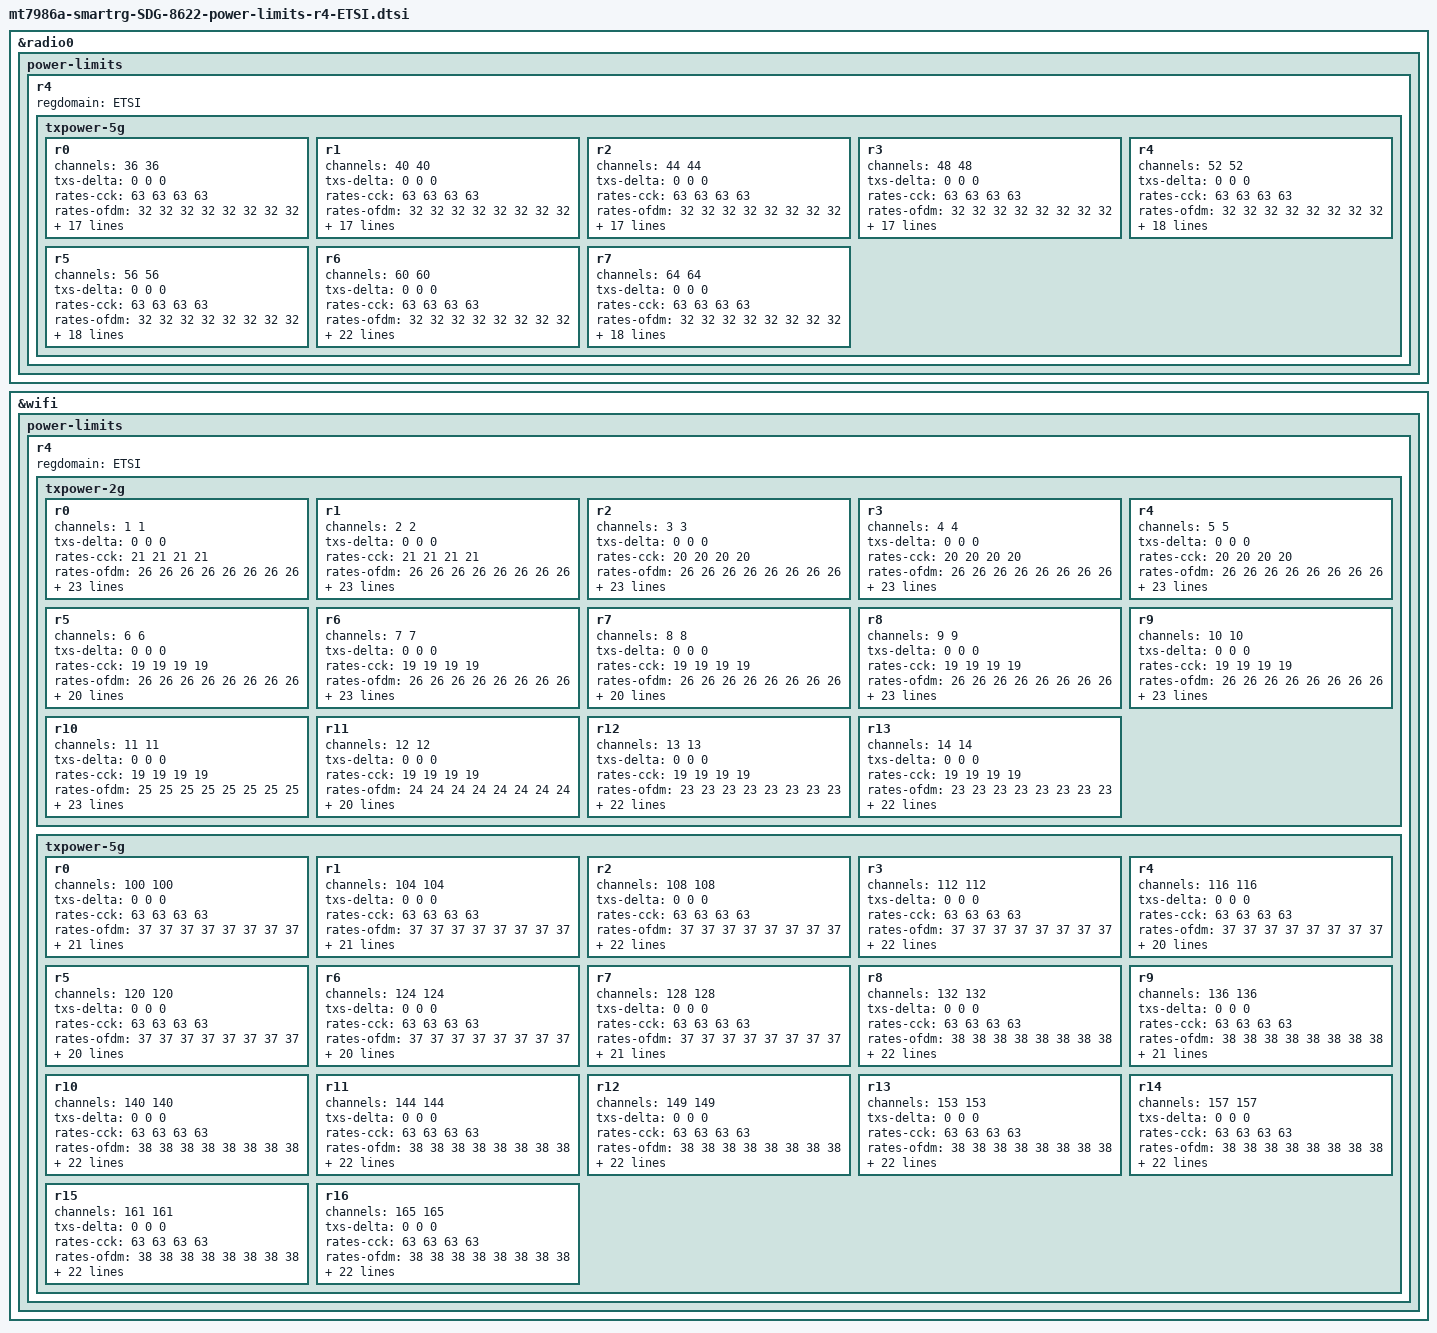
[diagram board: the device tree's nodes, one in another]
// SPDX-License-Identifier: (GPL-2.0 OR MIT)
/*
 * Copyright (C) 2022 SmartRG Inc.
 * Author: Chad Monroe <chad.monroe@smartrg.com>
 */

&radio0 {
	power-limits {
		r4 {
			regdomain = "ETSI";

			txpower-5g {
				r0 {
					channels = <36 36>;
					txs-delta = <0 0 0>;
					rates-cck = <63 63 63 63>;
					rates-ofdm = <32 32 32 32 32 32 32 32>;
					rates-mcs =
					<1 35 35 35 35 35 35 35 35 35 35>,
					<2 33 33 33 33 33 33 33 33 33 33>,
					<1 27 27 27 27 27 27 27 27 27 27>;
					rates-ru =
					<3 27 27 27 27 27 27 27 27 27 27 27 27>,
					<1 35 35 35 35 35 35 35 35 35 35 35 35>,
					<2 33 33 33 33 33 33 33 33 33 33 33 33>,
					<1 27 27 27 27 27 27 27 27 27 27 27 27>;
					paths-ofdm = <39 39 39 39>;
					paths-ofdm-bf = <0 40 40 40>;
					paths-ru =
					<3 27 27 27 27 27 27 27 27 27 27>,
					<1 35 35 35 35 35 35 35 35 35 35>,
					<2 33 33 33 33 33 33 33 33 33 33>,
					<1 27 27 27 27 27 27 27 27 27 27>;
					paths-ru-bf =
					<3 27 27 27 27 27 27 27 27 27 27>,
					<2 0 28 28 28 28 28 28 28 28 28>,
					<2 0 27 27 27 27 27 27 27 27 27>;
				};
				r1 {
					channels = <40 40>;
					txs-delta = <0 0 0>;
					rates-cck = <63 63 63 63>;
					rates-ofdm = <32 32 32 32 32 32 32 32>;
					rates-mcs =
					<1 35 35 35 35 35 35 35 35 35 35>,
					<2 33 33 33 33 33 33 33 33 33 33>,
					<1 27 27 27 27 27 27 27 27 27 27>;
					rates-ru =
					<3 27 27 27 27 27 27 27 27 27 27 27 27>,
					<1 35 35 35 35 35 35 35 35 35 35 35 35>,
					<2 33 33 33 33 33 33 33 33 33 33 33 33>,
					<1 27 27 27 27 27 27 27 27 27 27 27 27>;
					paths-ofdm = <40 40 40 40>;
					paths-ofdm-bf = <0 40 40 40>;
					paths-ru =
					<3 27 27 27 27 27 27 27 27 27 27>,
					<1 35 35 35 35 35 35 35 35 35 35>,
					<2 33 33 33 33 33 33 33 33 33 33>,
					<1 27 27 27 27 27 27 27 27 27 27>;
					paths-ru-bf =
					<3 27 27 27 27 27 27 27 27 27 27>,
					<2 0 28 28 28 28 28 28 28 28 28>,
					<2 0 27 27 27 27 27 27 27 27 27>;
				};
				r2 {
					channels = <44 44>;
					txs-delta = <0 0 0>;
					rates-cck = <63 63 63 63>;
					rates-ofdm = <32 32 32 32 32 32 32 32>;
					rates-mcs =
					<1 35 35 35 35 35 35 35 35 35 35>,
					<2 33 33 33 33 33 33 33 33 33 33>,
					<1 27 27 27 27 27 27 27 27 27 27>;
					rates-ru =
					<3 27 27 27 27 27 27 27 27 27 27 27 27>,
					<1 35 35 35 35 35 35 35 35 35 35 35 35>,
					<2 33 33 33 33 33 33 33 33 33 33 33 33>,
					<1 27 27 27 27 27 27 27 27 27 27 27 27>;
					paths-ofdm = <40 40 40 40>;
					paths-ofdm-bf = <0 40 40 40>;
					paths-ru =
					<3 27 27 27 27 27 27 27 27 27 27>,
					<1 35 35 35 35 35 35 35 35 35 35>,
					<2 33 33 33 33 33 33 33 33 33 33>,
					<1 27 27 27 27 27 27 27 27 27 27>;
					paths-ru-bf =
					<3 27 27 27 27 27 27 27 27 27 27>,
					<2 0 28 28 28 28 28 28 28 28 28>,
					<2 0 27 27 27 27 27 27 27 27 27>;
				};
				r3 {
					channels = <48 48>;
					txs-delta = <0 0 0>;
					rates-cck = <63 63 63 63>;
					rates-ofdm = <32 32 32 32 32 32 32 32>;
					rates-mcs =
					<1 35 35 35 35 35 35 35 35 35 35>,
					<2 33 33 33 33 33 33 33 33 33 33>,
					<1 27 27 27 27 27 27 27 27 27 27>;
					rates-ru =
					<3 27 27 27 27 27 27 27 27 27 27 27 27>,
					<1 35 35 35 35 35 35 35 35 35 35 35 35>,
					<2 33 33 33 33 33 33 33 33 33 33 33 33>,
					<1 27 27 27 27 27 27 27 27 27 27 27 27>;
					paths-ofdm = <39 39 39 39>;
					paths-ofdm-bf = <0 39 39 39>;
					paths-ru =
					<3 27 27 27 27 27 27 27 27 27 27>,
					<1 35 35 35 35 35 35 35 35 35 35>,
					<2 33 33 33 33 33 33 33 33 33 33>,
					<1 27 27 27 27 27 27 27 27 27 27>;
					paths-ru-bf =
					<3 27 27 27 27 27 27 27 27 27 27>,
					<2 0 28 28 28 28 28 28 28 28 28>,
					<2 0 27 27 27 27 27 27 27 27 27>;
				};
				r4 {
					channels = <52 52>;
					txs-delta = <0 0 0>;
					rates-cck = <63 63 63 63>;
					rates-ofdm = <32 32 32 32 32 32 32 32>;
					rates-mcs =
					<1 35 35 35 35 35 35 35 35 35 35>,
					<2 33 33 33 33 33 33 33 33 33 33>,
					<1 27 27 27 27 27 27 27 27 27 27>;
					rates-ru =
					<3 27 27 27 27 27 27 27 27 27 27 27 27>,
					<1 35 35 35 35 35 35 35 35 35 35 35 35>,
					<2 33 33 33 33 33 33 33 33 33 33 33 33>,
					<1 27 27 27 27 27 27 27 27 27 27 27 27>;
					paths-ofdm = <27 27 27 27>;
					paths-ofdm-bf = <0 27 27 27>;
					paths-ru =
					<3 27 27 27 27 27 27 27 27 27 27>,
					<1 35 35 35 35 35 35 35 35 35 35>,
					<2 33 33 33 33 33 33 33 33 33 33>,
					<1 27 27 27 27 27 27 27 27 27 27>;
					paths-ru-bf =
					<3 27 27 27 27 27 27 27 27 27 27>,
					<2 0 28 28 28 28 28 28 28 28 28>,
					<1 0 29 29 29 29 29 29 29 29 29>,
					<1 0 27 27 27 27 27 27 27 27 27>;
				};
				r5 {
					channels = <56 56>;
					txs-delta = <0 0 0>;
					rates-cck = <63 63 63 63>;
					rates-ofdm = <32 32 32 32 32 32 32 32>;
					rates-mcs =
					<1 35 35 35 35 35 35 35 35 35 35>,
					<2 33 33 33 33 33 33 33 33 33 33>,
					<1 27 27 27 27 27 27 27 27 27 27>;
					rates-ru =
					<3 27 27 27 27 27 27 27 27 27 27 27 27>,
					<1 35 35 35 35 35 35 35 35 35 35 35 35>,
					<2 33 33 33 33 33 33 33 33 33 33 33 33>,
					<1 27 27 27 27 27 27 27 27 27 27 27 27>;
					paths-ofdm = <27 27 27 27>;
					paths-ofdm-bf = <0 27 27 27>;
					paths-ru =
					<3 27 27 27 27 27 27 27 27 27 27>,
					<1 35 35 35 35 35 35 35 35 35 35>,
					<2 33 33 33 33 33 33 33 33 33 33>,
					<1 27 27 27 27 27 27 27 27 27 27>;
					paths-ru-bf =
					<3 27 27 27 27 27 27 27 27 27 27>,
					<2 0 28 28 28 28 28 28 28 28 28>,
					<1 0 29 29 29 29 29 29 29 29 29>,
					<1 0 27 27 27 27 27 27 27 27 27>;
				};
				r6 {
					channels = <60 60>;
					txs-delta = <0 0 0>;
					rates-cck = <63 63 63 63>;
					rates-ofdm = <32 32 32 32 32 32 32 32>;
					rates-mcs =
					<1 35 35 35 35 35 35 35 35 35 35>,
					<1 36 36 36 36 36 36 36 36 36 36>,
					<1 33 33 33 33 33 33 33 33 33 33>,
					<1 27 27 27 27 27 27 27 27 27 27>;
					rates-ru =
					<3 27 27 27 27 27 27 27 27 27 27 27 27>,
					<1 35 35 35 35 35 35 35 35 35 35 35 35>,
					<1 36 36 36 36 36 36 36 36 36 36 36 36>,
					<1 33 33 33 33 33 33 33 33 33 33 33 33>,
					<1 27 27 27 27 27 27 27 27 27 27 27 27>;
					paths-ofdm = <27 27 27 27>;
					paths-ofdm-bf = <0 27 27 27>;
					paths-ru =
					<3 27 27 27 27 27 27 27 27 27 27>,
					<1 35 35 35 35 35 35 35 35 35 35>,
					<1 36 36 36 36 36 36 36 36 36 36>,
					<1 33 33 33 33 33 33 33 33 33 33>,
					<1 27 27 27 27 27 27 27 27 27 27>;
					paths-ru-bf =
					<3 27 27 27 27 27 27 27 27 27 27>,
					<1 0 28 28 28 28 28 28 28 28 28>,
					<1 0 30 30 30 30 30 30 30 30 30>,
					<1 0 29 29 29 29 29 29 29 29 29>,
					<1 0 27 27 27 27 27 27 27 27 27>;
				};
				r7 {
					channels = <64 64>;
					txs-delta = <0 0 0>;
					rates-cck = <63 63 63 63>;
					rates-ofdm = <32 32 32 32 32 32 32 32>;
					rates-mcs =
					<2 36 36 36 36 36 36 36 36 36 36>,
					<1 33 33 33 33 33 33 33 33 33 33>,
					<1 27 27 27 27 27 27 27 27 27 27>;
					rates-ru =
					<3 27 27 27 27 27 27 27 27 27 27 27 27>,
					<2 36 36 36 36 36 36 36 36 36 36 36 36>,
					<1 33 33 33 33 33 33 33 33 33 33 33 33>,
					<1 27 27 27 27 27 27 27 27 27 27 27 27>;
					paths-ofdm = <27 27 27 27>;
					paths-ofdm-bf = <0 27 27 27>;
					paths-ru =
					<3 27 27 27 27 27 27 27 27 27 27>,
					<2 36 36 36 36 36 36 36 36 36 36>,
					<1 33 33 33 33 33 33 33 33 33 33>,
					<1 27 27 27 27 27 27 27 27 27 27>;
					paths-ru-bf =
					<3 27 27 27 27 27 27 27 27 27 27>,
					<2 0 30 30 30 30 30 30 30 30 30>,
					<1 0 29 29 29 29 29 29 29 29 29>,
					<1 0 27 27 27 27 27 27 27 27 27>;
				};
			};
		};
	};
};

&wifi {
	power-limits {
		r4 {
			regdomain = "ETSI";

			txpower-2g {
				r0 {
					channels = <1 1>;
					txs-delta = <0 0 0>;
					rates-cck = <21 21 21 21>;
					rates-ofdm = <26 26 26 26 26 26 26 26>;
					rates-mcs =
					<1 27 27 27 27 27 27 27 27 27 27>,
					<1 26 26 26 26 26 26 26 26 26 26>,
					<1 30 31 32 30 20 33 25 23 39 34>,
					<1 24 26 36 28 31 33 23 33 21 25>;
					rates-ru =
					<3 31 31 31 31 31 31 31 31 31 31 31 31>,
					<1 27 27 27 27 27 27 27 27 27 27 27 27>,
					<1 26 26 26 26 26 26 26 26 26 26 26 26>,
					<1 23 34 23 35 38 24 26 38 28 29 24 34>,
					<1 33 37 27 27 33 35 22 24 37 28 27 26>;
					paths-cck = <37 37 37 37>;
					paths-ofdm = <34 34 34 34>;
					paths-ofdm-bf = <0 33 33 33>;
					paths-ru =
					<3 28 28 28 28 28 28 28 28 28 28>,
					<1 27 27 27 27 27 27 27 27 27 27>,
					<1 26 26 26 26 26 26 26 26 26 26>,
					<1 27 38 20 26 28 20 29 21 36 30>,
					<1 35 39 24 31 25 30 25 29 27 39>;
					paths-ru-bf =
					<3 28 28 28 28 28 28 28 28 28 28>,
					<1 0 21 21 21 21 21 21 21 21 21>,
					<1 0 20 20 20 20 20 20 20 20 20>,
					<1 0 30 23 39 28 21 25 29 28 21>,
					<1 0 34 20 38 32 35 33 37 26 36>;
				};
				r1 {
					channels = <2 2>;
					txs-delta = <0 0 0>;
					rates-cck = <21 21 21 21>;
					rates-ofdm = <26 26 26 26 26 26 26 26>;
					rates-mcs =
					<1 27 27 27 27 27 27 27 27 27 27>,
					<1 26 26 26 26 26 26 26 26 26 26>,
					<1 29 26 37 20 35 27 31 23 27 23>,
					<1 28 33 25 28 27 23 24 33 24 21>;
					rates-ru =
					<3 31 31 31 31 31 31 31 31 31 31 31 31>,
					<1 27 27 27 27 27 27 27 27 27 27 27 27>,
					<1 26 26 26 26 26 26 26 26 26 26 26 26>,
					<1 28 22 29 39 21 39 29 24 23 32 25 21>,
					<1 23 32 30 39 29 27 36 26 22 33 34 29>;
					paths-cck = <38 38 38 38>;
					paths-ofdm = <35 35 35 35>;
					paths-ofdm-bf = <0 34 34 34>;
					paths-ru =
					<3 28 28 28 28 28 28 28 28 28 28>,
					<1 27 27 27 27 27 27 27 27 27 27>,
					<1 26 26 26 26 26 26 26 26 26 26>,
					<1 35 34 39 30 24 33 23 23 36 34>,
					<1 37 33 31 20 33 38 29 33 39 37>;
					paths-ru-bf =
					<3 28 28 28 28 28 28 28 28 28 28>,
					<1 0 21 21 21 21 21 21 21 21 21>,
					<1 0 20 20 20 20 20 20 20 20 20>,
					<1 0 29 21 24 33 24 30 22 22 31>,
					<1 0 38 34 33 23 25 39 30 31 32>;
				};
				r2 {
					channels = <3 3>;
					txs-delta = <0 0 0>;
					rates-cck = <20 20 20 20>;
					rates-ofdm = <26 26 26 26 26 26 26 26>;
					rates-mcs =
					<1 27 27 27 27 27 27 27 27 27 27>,
					<1 26 26 26 26 26 26 26 26 26 26>,
					<1 38 24 33 22 26 36 31 23 39 33>,
					<1 33 34 34 35 22 28 21 35 35 33>;
					rates-ru =
					<3 31 31 31 31 31 31 31 31 31 31 31 31>,
					<1 27 27 27 27 27 27 27 27 27 27 27 27>,
					<1 26 26 26 26 26 26 26 26 26 26 26 26>,
					<1 38 34 33 32 37 30 28 22 36 28 31 30>,
					<1 20 25 31 29 23 24 24 39 20 27 29 20>;
					paths-cck = <39 39 39 39>;
					paths-ofdm = <37 37 37 37>;
					paths-ofdm-bf = <0 35 35 35>;
					paths-ru =
					<3 28 28 28 28 28 28 28 28 28 28>,
					<1 27 27 27 27 27 27 27 27 27 27>,
					<1 26 26 26 26 26 26 26 26 26 26>,
					<1 30 38 34 37 35 31 39 20 26 23>,
					<1 33 25 35 25 32 27 35 22 29 35>;
					paths-ru-bf =
					<3 28 28 28 28 28 28 28 28 28 28>,
					<1 0 22 22 22 22 22 22 22 22 22>,
					<1 0 20 20 20 20 20 20 20 20 20>,
					<1 0 33 35 25 33 35 25 29 21 37>,
					<1 0 37 35 26 25 26 30 27 35 34>;
				};
				r3 {
					channels = <4 4>;
					txs-delta = <0 0 0>;
					rates-cck = <20 20 20 20>;
					rates-ofdm = <26 26 26 26 26 26 26 26>;
					rates-mcs =
					<1 27 27 27 27 27 27 27 27 27 27>,
					<1 26 26 26 26 26 26 26 26 26 26>,
					<1 38 23 25 21 27 38 20 23 39 36>,
					<1 23 24 20 26 37 31 29 30 22 36>;
					rates-ru =
					<3 31 31 31 31 31 31 31 31 31 31 31 31>,
					<1 27 27 27 27 27 27 27 27 27 27 27 27>,
					<1 26 26 26 26 26 26 26 26 26 26 26 26>,
					<1 37 34 38 35 35 39 38 26 39 37 24 34>,
					<1 29 31 24 39 24 22 20 28 34 31 30 21>;
					paths-cck = <41 41 41 41>;
					paths-ofdm = <39 39 39 39>;
					paths-ofdm-bf = <0 37 37 37>;
					paths-ru =
					<3 28 28 28 28 28 28 28 28 28 28>,
					<1 27 27 27 27 27 27 27 27 27 27>,
					<1 26 26 26 26 26 26 26 26 26 26>,
					<1 30 36 23 20 21 20 28 28 26 24>,
					<1 29 26 22 28 21 24 26 21 38 22>;
					paths-ru-bf =
					<3 28 28 28 28 28 28 28 28 28 28>,
					<1 0 22 22 22 22 22 22 22 22 22>,
					<1 0 20 20 20 20 20 20 20 20 20>,
					<1 0 28 37 30 26 20 38 35 21 27>,
					<1 0 39 39 32 25 26 33 32 33 25>;
				};
				r4 {
					channels = <5 5>;
					txs-delta = <0 0 0>;
					rates-cck = <20 20 20 20>;
					rates-ofdm = <26 26 26 26 26 26 26 26>;
					rates-mcs =
					<1 27 27 27 27 27 27 27 27 27 27>,
					<1 26 26 26 26 26 26 26 26 26 26>,
					<1 21 37 28 38 39 35 30 29 36 24>,
					<1 30 22 37 34 37 32 34 27 27 31>;
					rates-ru =
					<3 31 31 31 31 31 31 31 31 31 31 31 31>,
					<1 27 27 27 27 27 27 27 27 27 27 27 27>,
					<1 26 26 26 26 26 26 26 26 26 26 26 26>,
					<1 38 33 36 39 24 24 24 36 29 37 21 29>,
					<1 20 36 39 30 25 33 39 25 36 22 22 26>;
					paths-cck = <43 43 43 43>;
					paths-ofdm = <41 41 41 41>;
					paths-ofdm-bf = <0 38 38 38>;
					paths-ru =
					<3 28 28 28 28 28 28 28 28 28 28>,
					<1 27 27 27 27 27 27 27 27 27 27>,
					<1 26 26 26 26 26 26 26 26 26 26>,
					<1 25 31 23 25 27 25 26 28 25 34>,
					<1 29 38 27 22 37 25 33 35 34 31>;
					paths-ru-bf =
					<3 28 28 28 28 28 28 28 28 28 28>,
					<1 0 22 22 22 22 22 22 22 22 22>,
					<1 0 20 20 20 20 20 20 20 20 20>,
					<1 0 37 29 36 27 25 25 28 30 31>,
					<1 0 23 26 34 34 37 37 23 23 38>;
				};
				r5 {
					channels = <6 6>;
					txs-delta = <0 0 0>;
					rates-cck = <19 19 19 19>;
					rates-ofdm = <26 26 26 26 26 26 26 26>;
					rates-mcs =
					<2 27 27 27 27 27 27 27 27 27 27>,
					<1 33 39 30 36 33 37 38 39 38 35>,
					<1 29 23 22 36 23 21 28 35 36 33>;
					rates-ru =
					<3 31 31 31 31 31 31 31 31 31 31 31 31>,
					<2 27 27 27 27 27 27 27 27 27 27 27 27>,
					<1 23 23 31 30 21 30 27 33 27 23 31 23>,
					<1 39 36 25 24 38 36 24 30 29 39 21 22>;
					paths-cck = <44 44 44 44>;
					paths-ofdm = <42 42 42 42>;
					paths-ofdm-bf = <0 39 39 39>;
					paths-ru =
					<3 28 28 28 28 28 28 28 28 28 28>,
					<2 27 27 27 27 27 27 27 27 27 27>,
					<1 39 28 27 38 36 28 38 23 25 30>,
					<1 30 37 27 24 34 33 39 29 29 24>;
					paths-ru-bf =
					<3 28 28 28 28 28 28 28 28 28 28>,
					<1 0 22 22 22 22 22 22 22 22 22>,
					<1 0 20 20 20 20 20 20 20 20 20>,
					<1 0 33 24 27 27 36 22 26 27 38>,
					<1 0 20 30 32 26 39 36 28 38 34>;
				};
				r6 {
					channels = <7 7>;
					txs-delta = <0 0 0>;
					rates-cck = <19 19 19 19>;
					rates-ofdm = <26 26 26 26 26 26 26 26>;
					rates-mcs =
					<1 27 27 27 27 27 27 27 27 27 27>,
					<1 28 28 28 28 28 28 28 28 28 28>,
					<1 22 29 34 29 20 28 37 32 28 38>,
					<1 31 23 31 36 25 21 23 23 23 36>;
					rates-ru =
					<3 31 31 31 31 31 31 31 31 31 31 31 31>,
					<1 27 27 27 27 27 27 27 27 27 27 27 27>,
					<1 28 28 28 28 28 28 28 28 28 28 28 28>,
					<1 34 24 28 32 24 39 21 39 25 39 34 21>,
					<1 33 24 24 24 28 31 39 36 31 23 20 25>;
					paths-cck = <43 43 43 43>;
					paths-ofdm = <41 41 41 41>;
					paths-ofdm-bf = <0 37 37 37>;
					paths-ru =
					<3 28 28 28 28 28 28 28 28 28 28>,
					<1 27 27 27 27 27 27 27 27 27 27>,
					<1 28 28 28 28 28 28 28 28 28 28>,
					<1 24 26 29 29 32 34 26 29 21 37>,
					<1 27 33 25 22 35 20 37 32 30 37>;
					paths-ru-bf =
					<3 28 28 28 28 28 28 28 28 28 28>,
					<1 0 22 22 22 22 22 22 22 22 22>,
					<1 0 20 20 20 20 20 20 20 20 20>,
					<1 0 26 24 27 31 28 22 31 23 32>,
					<1 0 21 33 37 38 34 25 36 39 27>;
				};
				r7 {
					channels = <8 8>;
					txs-delta = <0 0 0>;
					rates-cck = <19 19 19 19>;
					rates-ofdm = <26 26 26 26 26 26 26 26>;
					rates-mcs =
					<2 27 27 27 27 27 27 27 27 27 27>,
					<1 27 20 34 28 20 20 30 36 31 35>,
					<1 37 20 34 38 35 28 20 32 21 25>;
					rates-ru =
					<3 31 31 31 31 31 31 31 31 31 31 31 31>,
					<2 27 27 27 27 27 27 27 27 27 27 27 27>,
					<1 21 28 28 37 39 27 21 36 29 24 28 32>,
					<1 26 27 22 28 32 20 30 26 29 28 31 38>;
					paths-cck = <41 41 41 41>;
					paths-ofdm = <39 39 39 39>;
					paths-ofdm-bf = <0 35 35 35>;
					paths-ru =
					<3 28 28 28 28 28 28 28 28 28 28>,
					<2 27 27 27 27 27 27 27 27 27 27>,
					<1 32 29 31 34 25 30 25 26 36 31>,
					<1 21 33 36 36 36 32 27 31 38 26>;
					paths-ru-bf =
					<3 28 28 28 28 28 28 28 28 28 28>,
					<1 0 22 22 22 22 22 22 22 22 22>,
					<1 0 20 20 20 20 20 20 20 20 20>,
					<1 0 24 29 21 27 21 25 39 35 21>,
					<1 0 36 38 38 32 30 32 39 28 34>;
				};
				r8 {
					channels = <9 9>;
					txs-delta = <0 0 0>;
					rates-cck = <19 19 19 19>;
					rates-ofdm = <26 26 26 26 26 26 26 26>;
					rates-mcs =
					<1 27 27 27 27 27 27 27 27 27 27>,
					<1 26 26 26 26 26 26 26 26 26 26>,
					<1 25 25 27 35 32 35 20 30 32 37>,
					<1 36 34 38 30 35 39 36 33 20 25>;
					rates-ru =
					<3 31 31 31 31 31 31 31 31 31 31 31 31>,
					<1 27 27 27 27 27 27 27 27 27 27 27 27>,
					<1 26 26 26 26 26 26 26 26 26 26 26 26>,
					<1 37 22 30 38 26 27 28 23 28 31 26 39>,
					<1 22 39 29 24 39 35 34 37 38 36 29 27>;
					paths-cck = <39 39 39 39>;
					paths-ofdm = <37 37 37 37>;
					paths-ofdm-bf = <0 33 33 33>;
					paths-ru =
					<3 28 28 28 28 28 28 28 28 28 28>,
					<1 27 27 27 27 27 27 27 27 27 27>,
					<1 26 26 26 26 26 26 26 26 26 26>,
					<1 24 27 27 22 25 33 24 32 23 21>,
					<1 33 22 27 35 34 30 21 25 20 35>;
					paths-ru-bf =
					<3 28 28 28 28 28 28 28 28 28 28>,
					<1 0 22 22 22 22 22 22 22 22 22>,
					<1 0 20 20 20 20 20 20 20 20 20>,
					<1 0 24 25 31 20 30 28 34 29 22>,
					<1 0 30 22 26 33 29 37 39 32 37>;
				};
				r9 {
					channels = <10 10>;
					txs-delta = <0 0 0>;
					rates-cck = <19 19 19 19>;
					rates-ofdm = <26 26 26 26 26 26 26 26>;
					rates-mcs =
					<1 27 27 27 27 27 27 27 27 27 27>,
					<1 26 26 26 26 26 26 26 26 26 26>,
					<1 31 39 34 29 38 29 38 35 24 20>,
					<1 36 34 25 32 32 28 39 25 35 24>;
					rates-ru =
					<3 31 31 31 31 31 31 31 31 31 31 31 31>,
					<1 27 27 27 27 27 27 27 27 27 27 27 27>,
					<1 26 26 26 26 26 26 26 26 26 26 26 26>,
					<1 36 31 30 32 20 24 39 25 36 29 22 28>,
					<1 32 28 37 35 24 25 20 38 35 33 29 27>;
					paths-cck = <38 38 38 38>;
					paths-ofdm = <35 35 35 35>;
					paths-ofdm-bf = <0 31 31 31>;
					paths-ru =
					<3 28 28 28 28 28 28 28 28 28 28>,
					<1 27 27 27 27 27 27 27 27 27 27>,
					<1 26 26 26 26 26 26 26 26 26 26>,
					<1 27 21 34 30 22 38 30 22 32 38>,
					<1 30 33 34 33 32 24 39 28 39 35>;
					paths-ru-bf =
					<3 28 28 28 28 28 28 28 28 28 28>,
					<1 0 22 22 22 22 22 22 22 22 22>,
					<1 0 20 20 20 20 20 20 20 20 20>,
					<1 0 35 30 38 21 38 23 21 35 28>,
					<1 0 36 35 21 30 38 23 32 33 31>;
				};
				r10 {
					channels = <11 11>;
					txs-delta = <0 0 0>;
					rates-cck = <19 19 19 19>;
					rates-ofdm = <25 25 25 25 25 25 25 25>;
					rates-mcs =
					<1 27 27 27 27 27 27 27 27 27 27>,
					<1 26 26 26 26 26 26 26 26 26 26>,
					<1 23 26 33 31 26 21 38 34 39 20>,
					<1 29 30 22 31 34 33 28 34 24 20>;
					rates-ru =
					<3 31 31 31 31 31 31 31 31 31 31 31 31>,
					<1 27 27 27 27 27 27 27 27 27 27 27 27>,
					<1 26 26 26 26 26 26 26 26 26 26 26 26>,
					<1 29 24 30 33 37 39 36 36 29 36 24 26>,
					<1 25 28 33 34 34 23 22 36 33 35 22 24>;
					paths-cck = <37 37 37 37>;
					paths-ofdm = <34 34 34 34>;
					paths-ofdm-bf = <0 29 29 29>;
					paths-ru =
					<3 28 28 28 28 28 28 28 28 28 28>,
					<1 27 27 27 27 27 27 27 27 27 27>,
					<1 26 26 26 26 26 26 26 26 26 26>,
					<1 26 38 39 25 37 26 32 38 36 24>,
					<1 23 36 27 26 29 36 28 31 36 37>;
					paths-ru-bf =
					<3 28 28 28 28 28 28 28 28 28 28>,
					<1 0 22 22 22 22 22 22 22 22 22>,
					<1 0 20 20 20 20 20 20 20 20 20>,
					<1 0 35 23 38 35 37 27 37 26 22>,
					<1 0 24 25 36 38 30 20 27 22 29>;
				};
				r11 {
					channels = <12 12>;
					txs-delta = <0 0 0>;
					rates-cck = <19 19 19 19>;
					rates-ofdm = <24 24 24 24 24 24 24 24>;
					rates-mcs =
					<2 26 26 26 26 26 26 26 26 26 26>,
					<1 20 36 37 24 24 29 34 27 31 24>,
					<1 29 22 21 38 24 25 31 23 20 21>;
					rates-ru =
					<3 31 31 31 31 31 31 31 31 31 31 31 31>,
					<2 26 26 26 26 26 26 26 26 26 26 26 26>,
					<1 31 26 23 24 36 34 24 30 24 25 31 24>,
					<1 35 23 20 39 28 25 24 30 34 33 32 32>;
					paths-cck = <37 37 37 37>;
					paths-ofdm = <34 34 34 34>;
					paths-ofdm-bf = <0 29 29 29>;
					paths-ru =
					<3 28 28 28 28 28 28 28 28 28 28>,
					<2 26 26 26 26 26 26 26 26 26 26>,
					<1 25 23 35 29 35 20 23 39 36 24>,
					<1 34 21 30 34 24 24 24 32 23 31>;
					paths-ru-bf =
					<3 28 28 28 28 28 28 28 28 28 28>,
					<1 0 21 21 21 21 21 21 21 21 21>,
					<1 0 20 20 20 20 20 20 20 20 20>,
					<1 0 25 25 20 21 25 29 37 29 22>,
					<1 0 29 37 25 37 35 31 30 39 39>;
				};
				r12 {
					channels = <13 13>;
					txs-delta = <0 0 0>;
					rates-cck = <19 19 19 19>;
					rates-ofdm = <23 23 23 23 23 23 23 23>;
					rates-mcs =
					<1 25 25 25 25 25 25 25 25 25 25>,
					<1 26 26 26 26 26 26 26 26 26 26>,
					<1 29 24 37 23 38 36 39 32 35 33>,
					<1 21 26 33 29 27 28 34 36 23 32>;
					rates-ru =
					<3 31 31 31 31 31 31 31 31 31 31 31 31>,
					<1 25 25 25 25 25 25 25 25 25 25 25 25>,
					<1 26 26 26 26 26 26 26 26 26 26 26 26>,
					<1 34 34 36 28 28 35 30 34 24 32 27 36>,
					<1 34 30 24 34 36 36 20 23 25 31 31 20>;
					paths-cck = <37 37 37 37>;
					paths-ofdm = <34 34 34 34>;
					paths-ofdm-bf = <0 29 29 29>;
					paths-ru =
					<3 28 28 28 28 28 28 28 28 28 28>,
					<1 25 25 25 25 25 25 25 25 25 25>,
					<1 26 26 26 26 26 26 26 26 26 26>,
					<1 28 23 27 25 39 20 23 27 36 30>,
					<1 25 23 34 26 37 26 32 37 36 31>;
					paths-ru-bf =
					<3 28 28 28 28 28 28 28 28 28 28>,
					<2 0 20 20 20 20 20 20 20 20 20>,
					<1 0 31 32 31 34 33 27 36 22 20>,
					<1 0 32 25 23 39 20 28 37 21 32>;
				};
				r13 {
					channels = <14 14>;
					txs-delta = <0 0 0>;
					rates-cck = <19 19 19 19>;
					rates-ofdm = <23 23 23 23 23 23 23 23>;
					rates-mcs =
					<1 25 25 25 25 25 25 25 25 25 25>,
					<1 26 26 26 26 26 26 26 26 26 26>,
					<1 38 29 37 27 28 24 32 37 33 22>,
					<1 31 37 23 28 23 35 21 22 20 34>;
					rates-ru =
					<3 31 31 31 31 31 31 31 31 31 31 31 31>,
					<1 25 25 25 25 25 25 25 25 25 25 25 25>,
					<1 26 26 26 26 26 26 26 26 26 26 26 26>,
					<1 30 28 21 29 34 23 32 31 24 26 36 30>,
					<1 22 28 32 29 24 20 23 21 33 33 22 24>;
					paths-cck = <37 37 37 37>;
					paths-ofdm = <34 34 34 34>;
					paths-ofdm-bf = <0 29 29 29>;
					paths-ru =
					<3 28 28 28 28 28 28 28 28 28 28>,
					<1 25 25 25 25 25 25 25 25 25 25>,
					<1 26 26 26 26 26 26 26 26 26 26>,
					<1 26 36 26 37 26 20 36 21 30 30>,
					<1 24 33 33 27 25 27 29 39 37 30>;
					paths-ru-bf =
					<3 28 28 28 28 28 28 28 28 28 28>,
					<2 0 20 20 20 20 20 20 20 20 20>,
					<1 0 36 24 22 27 32 29 36 36 37>,
					<1 0 33 29 29 36 32 29 36 25 39>;
				};
			};

			txpower-5g {
				r0 {
					channels = <100 100>;
					txs-delta = <0 0 0>;
					rates-cck = <63 63 63 63>;
					rates-ofdm = <37 37 37 37 37 37 37 37>;
					rates-mcs =
					<1 35 35 35 35 35 35 35 35 35 35>,
					<1 36 36 36 36 36 36 36 36 36 36>,
					<1 34 34 34 34 34 34 34 34 34 34>,
					<1 32 32 32 32 32 32 32 32 32 32>;
					rates-ru =
					<3 27 27 27 27 27 27 27 27 27 27 27 27>,
					<1 35 35 35 35 35 35 35 35 35 35 35 35>,
					<1 36 36 36 36 36 36 36 36 36 36 36 36>,
					<1 34 34 34 34 34 34 34 34 34 34 34 34>,
					<1 32 32 32 32 32 32 32 32 32 32 32 32>;
					paths-ofdm = <27 27 27 27>;
					paths-ofdm-bf = <0 27 27 27>;
					paths-ru =
					<3 27 27 27 27 27 27 27 27 27 27>,
					<1 35 35 35 35 35 35 35 35 35 35>,
					<1 36 36 36 36 36 36 36 36 36 36>,
					<1 34 34 34 34 34 34 34 34 34 34>,
					<1 32 32 32 32 32 32 32 32 32 32>;
					paths-ru-bf =
					<3 27 27 27 27 27 27 27 27 27 27>,
					<1 0 36 36 36 36 36 36 36 36 36>,
					<2 0 32 32 32 32 32 32 32 32 32>,
					<1 0 34 34 34 34 34 34 34 34 34>;
				};
				r1 {
					channels = <104 104>;
					txs-delta = <0 0 0>;
					rates-cck = <63 63 63 63>;
					rates-ofdm = <37 37 37 37 37 37 37 37>;
					rates-mcs =
					<1 35 35 35 35 35 35 35 35 35 35>,
					<1 36 36 36 36 36 36 36 36 36 36>,
					<1 34 34 34 34 34 34 34 34 34 34>,
					<1 32 32 32 32 32 32 32 32 32 32>;
					rates-ru =
					<3 27 27 27 27 27 27 27 27 27 27 27 27>,
					<1 35 35 35 35 35 35 35 35 35 35 35 35>,
					<1 36 36 36 36 36 36 36 36 36 36 36 36>,
					<1 34 34 34 34 34 34 34 34 34 34 34 34>,
					<1 32 32 32 32 32 32 32 32 32 32 32 32>;
					paths-ofdm = <28 28 28 28>;
					paths-ofdm-bf = <0 28 28 28>;
					paths-ru =
					<3 27 27 27 27 27 27 27 27 27 27>,
					<1 35 35 35 35 35 35 35 35 35 35>,
					<1 36 36 36 36 36 36 36 36 36 36>,
					<1 34 34 34 34 34 34 34 34 34 34>,
					<1 32 32 32 32 32 32 32 32 32 32>;
					paths-ru-bf =
					<3 27 27 27 27 27 27 27 27 27 27>,
					<1 0 36 36 36 36 36 36 36 36 36>,
					<2 0 32 32 32 32 32 32 32 32 32>,
					<1 0 34 34 34 34 34 34 34 34 34>;
				};
				r2 {
					channels = <108 108>;
					txs-delta = <0 0 0>;
					rates-cck = <63 63 63 63>;
					rates-ofdm = <37 37 37 37 37 37 37 37>;
					rates-mcs =
					<1 35 35 35 35 35 35 35 35 35 35>,
					<1 37 37 37 37 37 37 37 37 37 37>,
					<1 34 34 34 34 34 34 34 34 34 34>,
					<1 32 32 32 32 32 32 32 32 32 32>;
					rates-ru =
					<3 27 27 27 27 27 27 27 27 27 27 27 27>,
					<1 35 35 35 35 35 35 35 35 35 35 35 35>,
					<1 37 37 37 37 37 37 37 37 37 37 37 37>,
					<1 34 34 34 34 34 34 34 34 34 34 34 34>,
					<1 32 32 32 32 32 32 32 32 32 32 32 32>;
					paths-ofdm = <28 28 28 28>;
					paths-ofdm-bf = <0 28 28 28>;
					paths-ru =
					<3 27 27 27 27 27 27 27 27 27 27>,
					<1 35 35 35 35 35 35 35 35 35 35>,
					<1 37 37 37 37 37 37 37 37 37 37>,
					<1 34 34 34 34 34 34 34 34 34 34>,
					<1 32 32 32 32 32 32 32 32 32 32>;
					paths-ru-bf =
					<3 27 27 27 27 27 27 27 27 27 27>,
					<1 0 36 36 36 36 36 36 36 36 36>,
					<1 0 33 33 33 33 33 33 33 33 33>,
					<1 0 32 32 32 32 32 32 32 32 32>,
					<1 0 34 34 34 34 34 34 34 34 34>;
				};
				r3 {
					channels = <112 112>;
					txs-delta = <0 0 0>;
					rates-cck = <63 63 63 63>;
					rates-ofdm = <37 37 37 37 37 37 37 37>;
					rates-mcs =
					<1 35 35 35 35 35 35 35 35 35 35>,
					<1 37 37 37 37 37 37 37 37 37 37>,
					<1 34 34 34 34 34 34 34 34 34 34>,
					<1 32 32 32 32 32 32 32 32 32 32>;
					rates-ru =
					<3 27 27 27 27 27 27 27 27 27 27 27 27>,
					<1 35 35 35 35 35 35 35 35 35 35 35 35>,
					<1 37 37 37 37 37 37 37 37 37 37 37 37>,
					<1 34 34 34 34 34 34 34 34 34 34 34 34>,
					<1 32 32 32 32 32 32 32 32 32 32 32 32>;
					paths-ofdm = <28 28 28 28>;
					paths-ofdm-bf = <0 28 28 28>;
					paths-ru =
					<3 27 27 27 27 27 27 27 27 27 27>,
					<1 35 35 35 35 35 35 35 35 35 35>,
					<1 37 37 37 37 37 37 37 37 37 37>,
					<1 34 34 34 34 34 34 34 34 34 34>,
					<1 32 32 32 32 32 32 32 32 32 32>;
					paths-ru-bf =
					<3 27 27 27 27 27 27 27 27 27 27>,
					<1 0 36 36 36 36 36 36 36 36 36>,
					<1 0 33 33 33 33 33 33 33 33 33>,
					<1 0 32 32 32 32 32 32 32 32 32>,
					<1 0 34 34 34 34 34 34 34 34 34>;
				};
				r4 {
					channels = <116 116>;
					txs-delta = <0 0 0>;
					rates-cck = <63 63 63 63>;
					rates-ofdm = <37 37 37 37 37 37 37 37>;
					rates-mcs =
					<1 36 36 36 36 36 36 36 36 36 36>,
					<1 38 38 38 38 38 38 38 38 38 38>,
					<1 36 36 36 36 36 36 36 36 36 36>,
					<1 32 32 32 32 32 32 32 32 32 32>;
					rates-ru =
					<3 27 27 27 27 27 27 27 27 27 27 27 27>,
					<1 36 36 36 36 36 36 36 36 36 36 36 36>,
					<1 38 38 38 38 38 38 38 38 38 38 38 38>,
					<1 36 36 36 36 36 36 36 36 36 36 36 36>,
					<1 32 32 32 32 32 32 32 32 32 32 32 32>;
					paths-ofdm = <28 28 28 28>;
					paths-ofdm-bf = <0 28 28 28>;
					paths-ru =
					<3 27 27 27 27 27 27 27 27 27 27>,
					<1 36 36 36 36 36 36 36 36 36 36>,
					<1 38 38 38 38 38 38 38 38 38 38>,
					<1 36 36 36 36 36 36 36 36 36 36>,
					<1 32 32 32 32 32 32 32 32 32 32>;
					paths-ru-bf =
					<3 27 27 27 27 27 27 27 27 27 27>,
					<1 0 36 36 36 36 36 36 36 36 36>,
					<3 0 34 34 34 34 34 34 34 34 34>;
				};
				r5 {
					channels = <120 120>;
					txs-delta = <0 0 0>;
					rates-cck = <63 63 63 63>;
					rates-ofdm = <37 37 37 37 37 37 37 37>;
					rates-mcs =
					<1 36 36 36 36 36 36 36 36 36 36>,
					<1 38 38 38 38 38 38 38 38 38 38>,
					<1 36 36 36 36 36 36 36 36 36 36>,
					<1 32 32 32 32 32 32 32 32 32 32>;
					rates-ru =
					<3 27 27 27 27 27 27 27 27 27 27 27 27>,
					<1 36 36 36 36 36 36 36 36 36 36 36 36>,
					<1 38 38 38 38 38 38 38 38 38 38 38 38>,
					<1 36 36 36 36 36 36 36 36 36 36 36 36>,
					<1 32 32 32 32 32 32 32 32 32 32 32 32>;
					paths-ofdm = <28 21 20 39>;
					paths-ofdm-bf = <0 22 35 28>;
					paths-ru =
					<3 27 27 27 27 27 27 27 27 27 27>,
					<1 36 36 36 36 36 36 36 36 36 36>,
					<1 38 38 38 38 38 38 38 38 38 38>,
					<1 36 36 36 36 36 36 36 36 36 36>,
					<1 32 32 32 32 32 32 32 32 32 32>;
					paths-ru-bf =
					<3 27 27 27 27 27 27 27 27 27 27>,
					<1 0 36 36 36 36 36 36 36 36 36>,
					<3 0 34 34 34 34 34 34 34 34 34>;
				};
				r6 {
					channels = <124 124>;
					txs-delta = <0 0 0>;
					rates-cck = <63 63 63 63>;
					rates-ofdm = <37 37 37 37 37 37 37 37>;
					rates-mcs =
					<1 36 36 36 36 36 36 36 36 36 36>,
					<1 39 39 39 39 39 39 39 39 39 39>,
					<1 36 36 36 36 36 36 36 36 36 36>,
					<1 32 32 32 32 32 32 32 32 32 32>;
					rates-ru =
					<3 27 27 27 27 27 27 27 27 27 27 27 27>,
					<1 36 36 36 36 36 36 36 36 36 36 36 36>,
					<1 39 39 39 39 39 39 39 39 39 39 39 39>,
					<1 36 36 36 36 36 36 36 36 36 36 36 36>,
					<1 32 32 32 32 32 32 32 32 32 32 32 32>;
					paths-ofdm = <28 37 33 28>;
					paths-ofdm-bf = <0 22 26 33>;
					paths-ru =
					<3 27 27 27 27 27 27 27 27 27 27>,
					<1 36 36 36 36 36 36 36 36 36 36>,
					<1 39 39 39 39 39 39 39 39 39 39>,
					<1 36 36 36 36 36 36 36 36 36 36>,
					<1 32 32 32 32 32 32 32 32 32 32>;
					paths-ru-bf =
					<3 27 27 27 27 27 27 27 27 27 27>,
					<2 0 35 35 35 35 35 35 35 35 35>,
					<2 0 34 34 34 34 34 34 34 34 34>;
				};
				r7 {
					channels = <128 128>;
					txs-delta = <0 0 0>;
					rates-cck = <63 63 63 63>;
					rates-ofdm = <37 37 37 37 37 37 37 37>;
					rates-mcs =
					<1 36 36 36 36 36 36 36 36 36 36>,
					<1 39 39 39 39 39 39 39 39 39 39>,
					<1 36 36 36 36 36 36 36 36 36 36>,
					<1 32 32 32 32 32 32 32 32 32 32>;
					rates-ru =
					<3 27 27 27 27 27 27 27 27 27 27 27 27>,
					<1 36 36 36 36 36 36 36 36 36 36 36 36>,
					<1 39 39 39 39 39 39 39 39 39 39 39 39>,
					<1 36 36 36 36 36 36 36 36 36 36 36 36>,
					<1 32 32 32 32 32 32 32 32 32 32 32 32>;
					paths-ofdm = <28 24 29 37>;
					paths-ofdm-bf = <0 20 32 30>;
					paths-ru =
					<3 27 27 27 27 27 27 27 27 27 27>,
					<1 36 36 36 36 36 36 36 36 36 36>,
					<1 39 39 39 39 39 39 39 39 39 39>,
					<1 36 36 36 36 36 36 36 36 36 36>,
					<1 32 32 32 32 32 32 32 32 32 32>;
					paths-ru-bf =
					<3 27 27 27 27 27 27 27 27 27 27>,
					<1 0 34 34 34 34 34 34 34 34 34>,
					<1 0 35 35 35 35 35 35 35 35 35>,
					<2 0 34 34 34 34 34 34 34 34 34>;
				};
				r8 {
					channels = <132 132>;
					txs-delta = <0 0 0>;
					rates-cck = <63 63 63 63>;
					rates-ofdm = <38 38 38 38 38 38 38 38>;
					rates-mcs =
					<1 37 37 37 37 37 37 37 37 37 37>,
					<1 39 39 39 39 39 39 39 39 39 39>,
					<1 36 36 36 36 36 36 36 36 36 36>,
					<1 30 27 24 30 27 24 35 31 38 39>;
					rates-ru =
					<3 27 27 27 27 27 27 27 27 27 27 27 27>,
					<1 37 37 37 37 37 37 37 37 37 37 37 37>,
					<1 39 39 39 39 39 39 39 39 39 39 39 39>,
					<1 36 36 36 36 36 36 36 36 36 36 36 36>,
					<1 27 27 27 27 27 27 27 27 27 27 27 27>;
					paths-ofdm = <28 31 36 32>;
					paths-ofdm-bf = <0 20 29 21>;
					paths-ru =
					<3 27 27 27 27 27 27 27 27 27 27>,
					<1 37 37 37 37 37 37 37 37 37 37>,
					<1 39 39 39 39 39 39 39 39 39 39>,
					<1 36 36 36 36 36 36 36 36 36 36>,
					<1 30 30 30 30 30 30 30 30 30 30>;
					paths-ru-bf =
					<3 27 27 27 27 27 27 27 27 27 27>,
					<1 0 33 33 33 33 33 33 33 33 33>,
					<1 0 35 35 35 35 35 35 35 35 35>,
					<1 0 34 34 34 34 34 34 34 34 34>,
					<1 0 34 20 24 20 33 23 38 26 25>;
				};
				r9 {
					channels = <136 136>;
					txs-delta = <0 0 0>;
					rates-cck = <63 63 63 63>;
					rates-ofdm = <38 38 38 38 38 38 38 38>;
					rates-mcs =
					<1 37 37 37 37 37 37 37 37 37 37>,
					<1 39 39 39 39 39 39 39 39 39 39>,
					<1 36 36 36 36 36 36 36 36 36 36>,
					<1 36 37 38 34 22 33 32 23 24 37>;
					rates-ru =
					<3 27 27 27 27 27 27 27 27 27 27 27 27>,
					<1 37 37 37 37 37 37 37 37 37 37 37 37>,
					<1 39 39 39 39 39 39 39 39 39 39 39 39>,
					<1 36 36 36 36 36 36 36 36 36 36 36 36>,
					<1 27 27 27 27 27 27 27 27 27 27 27 27>;
					paths-ofdm = <28 20 26 27>;
					paths-ofdm-bf = <0 31 39 36>;
					paths-ru =
					<3 27 27 27 27 27 27 27 27 27 27>,
					<1 37 37 37 37 37 37 37 37 37 37>,
					<1 39 39 39 39 39 39 39 39 39 39>,
					<2 36 36 36 36 36 36 36 36 36 36>;
					paths-ru-bf =
					<3 27 27 27 27 27 27 27 27 27 27>,
					<1 0 32 32 32 32 32 32 32 32 32>,
					<1 0 35 35 35 35 35 35 35 35 35>,
					<1 0 34 34 34 34 34 34 34 34 34>,
					<1 0 22 30 27 30 31 34 36 34 27>;
				};
				r10 {
					channels = <140 140>;
					txs-delta = <0 0 0>;
					rates-cck = <63 63 63 63>;
					rates-ofdm = <38 38 38 38 38 38 38 38>;
					rates-mcs =
					<1 37 37 37 37 37 37 37 37 37 37>,
					<1 39 39 39 39 39 39 39 39 39 39>,
					<1 36 36 36 36 36 36 36 36 36 36>,
					<1 32 29 37 27 27 25 21 31 35 20>;
					rates-ru =
					<3 27 27 27 27 27 27 27 27 27 27 27 27>,
					<1 37 37 37 37 37 37 37 37 37 37 37 37>,
					<1 39 39 39 39 39 39 39 39 39 39 39 39>,
					<1 36 36 36 36 36 36 36 36 36 36 36 36>,
					<1 27 27 27 27 27 27 27 27 27 27 27 27>;
					paths-ofdm = <28 28 28 28>;
					paths-ofdm-bf = <0 28 28 28>;
					paths-ru =
					<3 32 32 32 32 32 32 32 32 32 32>,
					<1 37 37 37 37 37 37 37 37 37 37>,
					<1 39 39 39 39 39 39 39 39 39 39>,
					<1 36 36 36 36 36 36 36 36 36 36>,
					<1 32 32 32 32 32 32 32 32 32 32>;
					paths-ru-bf =
					<3 32 32 32 32 32 32 32 32 32 32>,
					<1 0 31 31 31 31 31 31 31 31 31>,
					<1 0 35 35 35 35 35 35 35 35 35>,
					<1 0 34 34 34 34 34 34 34 34 34>,
					<1 0 32 29 20 32 30 27 32 24 26>;
				};
				r11 {
					channels = <144 144>;
					txs-delta = <0 0 0>;
					rates-cck = <63 63 63 63>;
					rates-ofdm = <38 38 38 38 38 38 38 38>;
					rates-mcs =
					<1 37 37 37 37 37 37 37 37 37 37>,
					<1 39 39 39 39 39 39 39 39 39 39>,
					<1 36 36 36 36 36 36 36 36 36 36>,
					<1 38 39 29 38 29 22 33 35 38 28>;
					rates-ru =
					<3 27 27 27 27 27 27 27 27 27 27 27 27>,
					<1 37 37 37 37 37 37 37 37 37 37 37 37>,
					<1 39 39 39 39 39 39 39 39 39 39 39 39>,
					<1 36 36 36 36 36 36 36 36 36 36 36 36>,
					<1 27 27 27 27 27 27 27 27 27 27 27 27>;
					paths-ofdm = <27 27 27 27>;
					paths-ofdm-bf = <0 27 27 27>;
					paths-ru =
					<3 38 38 38 38 38 38 38 38 38 38>,
					<1 37 37 37 37 37 37 37 37 37 37>,
					<1 39 39 39 39 39 39 39 39 39 39>,
					<1 36 36 36 36 36 36 36 36 36 36>,
					<1 38 38 38 38 38 38 38 38 38 38>;
					paths-ru-bf =
					<3 38 38 38 38 38 38 38 38 38 38>,
					<1 0 31 31 31 31 31 31 31 31 31>,
					<1 0 35 35 35 35 35 35 35 35 35>,
					<1 0 34 34 34 34 34 34 34 34 34>,
					<1 0 26 21 31 35 28 29 32 28 38>;
				};
				r12 {
					channels = <149 149>;
					txs-delta = <0 0 0>;
					rates-cck = <63 63 63 63>;
					rates-ofdm = <38 38 38 38 38 38 38 38>;
					rates-mcs =
					<1 37 37 37 37 37 37 37 37 37 37>,
					<1 39 39 39 39 39 39 39 39 39 39>,
					<1 36 36 36 36 36 36 36 36 36 36>,
					<1 25 25 30 32 37 31 24 29 38 21>;
					rates-ru =
					<3 41 41 41 41 41 41 41 41 41 41 41 41>,
					<1 37 37 37 37 37 37 37 37 37 37 37 37>,
					<1 39 39 39 39 39 39 39 39 39 39 39 39>,
					<1 36 36 36 36 36 36 36 36 36 36 36 36>,
					<1 41 41 41 41 41 41 41 41 41 41 41 41>;
					paths-ofdm = <46 46 46 46>;
					paths-ofdm-bf = <0 39 39 39>;
					paths-ru =
					<3 21 21 21 21 21 21 21 21 21 21>,
					<1 37 37 37 37 37 37 37 37 37 37>,
					<1 39 39 39 39 39 39 39 39 39 39>,
					<1 36 36 36 36 36 36 36 36 36 36>,
					<1 25 25 25 25 25 25 25 25 25 25>;
					paths-ru-bf =
					<3 21 21 21 21 21 21 21 21 21 21>,
					<1 0 31 31 31 31 31 31 31 31 31>,
					<1 0 35 35 35 35 35 35 35 35 35>,
					<1 0 34 34 34 34 34 34 34 34 34>,
					<1 0 31 23 21 36 31 31 36 36 23>;
				};
				r13 {
					channels = <153 153>;
					txs-delta = <0 0 0>;
					rates-cck = <63 63 63 63>;
					rates-ofdm = <38 38 38 38 38 38 38 38>;
					rates-mcs =
					<1 37 37 37 37 37 37 37 37 37 37>,
					<1 39 39 39 39 39 39 39 39 39 39>,
					<1 36 36 36 36 36 36 36 36 36 36>,
					<1 27 25 34 27 36 30 26 36 21 34>;
					rates-ru =
					<3 41 41 41 41 41 41 41 41 41 41 41 41>,
					<1 37 37 37 37 37 37 37 37 37 37 37 37>,
					<1 39 39 39 39 39 39 39 39 39 39 39 39>,
					<1 36 36 36 36 36 36 36 36 36 36 36 36>,
					<1 41 41 41 41 41 41 41 41 41 41 41 41>;
					paths-ofdm = <46 46 46 46>;
					paths-ofdm-bf = <0 39 39 39>;
					paths-ru =
					<3 21 21 21 21 21 21 21 21 21 21>,
					<1 37 37 37 37 37 37 37 37 37 37>,
					<1 39 39 39 39 39 39 39 39 39 39>,
					<1 36 36 36 36 36 36 36 36 36 36>,
					<1 27 27 27 27 27 27 27 27 27 27>;
					paths-ru-bf =
					<3 21 21 21 21 21 21 21 21 21 21>,
					<1 0 31 31 31 31 31 31 31 31 31>,
					<1 0 35 35 35 35 35 35 35 35 35>,
					<1 0 34 34 34 34 34 34 34 34 34>,
					<1 0 20 34 37 24 24 32 24 22 32>;
				};
				r14 {
					channels = <157 157>;
					txs-delta = <0 0 0>;
					rates-cck = <63 63 63 63>;
					rates-ofdm = <38 38 38 38 38 38 38 38>;
					rates-mcs =
					<1 37 37 37 37 37 37 37 37 37 37>,
					<1 39 39 39 39 39 39 39 39 39 39>,
					<1 36 36 36 36 36 36 36 36 36 36>,
					<1 30 32 21 22 25 28 34 39 23 36>;
					rates-ru =
					<3 41 41 41 41 41 41 41 41 41 41 41 41>,
					<1 37 37 37 37 37 37 37 37 37 37 37 37>,
					<1 39 39 39 39 39 39 39 39 39 39 39 39>,
					<1 36 36 36 36 36 36 36 36 36 36 36 36>,
					<1 41 41 41 41 41 41 41 41 41 41 41 41>;
					paths-ofdm = <46 46 46 46>;
					paths-ofdm-bf = <0 39 39 39>;
					paths-ru =
					<3 21 21 21 21 21 21 21 21 21 21>,
					<1 37 37 37 37 37 37 37 37 37 37>,
					<1 39 39 39 39 39 39 39 39 39 39>,
					<1 36 36 36 36 36 36 36 36 36 36>,
					<1 30 30 30 30 30 30 30 30 30 30>;
					paths-ru-bf =
					<3 21 21 21 21 21 21 21 21 21 21>,
					<1 0 31 31 31 31 31 31 31 31 31>,
					<1 0 35 35 35 35 35 35 35 35 35>,
					<1 0 34 34 34 34 34 34 34 34 34>,
					<1 0 22 23 23 31 29 30 38 26 28>;
				};
				r15 {
					channels = <161 161>;
					txs-delta = <0 0 0>;
					rates-cck = <63 63 63 63>;
					rates-ofdm = <38 38 38 38 38 38 38 38>;
					rates-mcs =
					<1 37 37 37 37 37 37 37 37 37 37>,
					<1 39 39 39 39 39 39 39 39 39 39>,
					<1 36 36 36 36 36 36 36 36 36 36>,
					<1 26 23 35 27 38 27 21 34 39 27>;
					rates-ru =
					<3 41 41 41 41 41 41 41 41 41 41 41 41>,
					<1 37 37 37 37 37 37 37 37 37 37 37 37>,
					<1 39 39 39 39 39 39 39 39 39 39 39 39>,
					<1 36 36 36 36 36 36 36 36 36 36 36 36>,
					<1 41 41 41 41 41 41 41 41 41 41 41 41>;
					paths-ofdm = <46 46 46 46>;
					paths-ofdm-bf = <0 39 39 39>;
					paths-ru =
					<3 21 21 21 21 21 21 21 21 21 21>,
					<1 37 37 37 37 37 37 37 37 37 37>,
					<1 39 39 39 39 39 39 39 39 39 39>,
					<1 36 36 36 36 36 36 36 36 36 36>,
					<1 26 26 26 26 26 26 26 26 26 26>;
					paths-ru-bf =
					<3 21 21 21 21 21 21 21 21 21 21>,
					<1 0 31 31 31 31 31 31 31 31 31>,
					<1 0 35 35 35 35 35 35 35 35 35>,
					<1 0 34 34 34 34 34 34 34 34 34>,
					<1 0 34 39 38 25 28 31 23 30 28>;
				};
				r16 {
					channels = <165 165>;
					txs-delta = <0 0 0>;
					rates-cck = <63 63 63 63>;
					rates-ofdm = <38 38 38 38 38 38 38 38>;
					rates-mcs =
					<1 37 37 37 37 37 37 37 37 37 37>,
					<1 39 39 39 39 39 39 39 39 39 39>,
					<1 36 36 36 36 36 36 36 36 36 36>,
					<1 21 24 20 31 28 31 20 21 29 27>;
					rates-ru =
					<3 41 41 41 41 41 41 41 41 41 41 41 41>,
					<1 37 37 37 37 37 37 37 37 37 37 37 37>,
					<1 39 39 39 39 39 39 39 39 39 39 39 39>,
					<1 36 36 36 36 36 36 36 36 36 36 36 36>,
					<1 41 41 41 41 41 41 41 41 41 41 41 41>;
					paths-ofdm = <46 46 46 46>;
					paths-ofdm-bf = <0 39 39 39>;
					paths-ru =
					<3 21 21 21 21 21 21 21 21 21 21>,
					<1 37 37 37 37 37 37 37 37 37 37>,
					<1 39 39 39 39 39 39 39 39 39 39>,
					<1 36 36 36 36 36 36 36 36 36 36>,
					<1 21 21 21 21 21 21 21 21 21 21>;
					paths-ru-bf =
					<3 21 21 21 21 21 21 21 21 21 21>,
					<1 0 31 31 31 31 31 31 31 31 31>,
					<1 0 35 35 35 35 35 35 35 35 35>,
					<1 0 34 34 34 34 34 34 34 34 34>,
					<1 0 35 32 29 37 34 27 28 28 33>;
				};
			};
		};
	};
};
